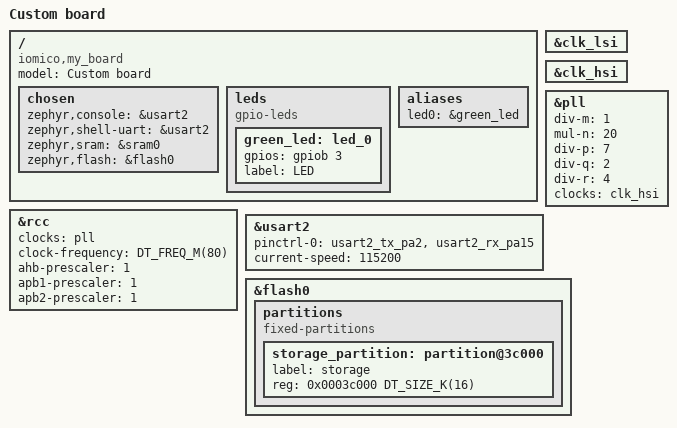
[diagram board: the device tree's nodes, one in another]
/dts-v1/;
#include <st/l4/stm32l432Xc.dtsi>
#include <st/l4/stm32l432k(b-c)ux-pinctrl.dtsi>

/ {
	model = "Custom board";
	compatible = "iomico,my_board";

	chosen {
		zephyr,console = &usart2;
		zephyr,shell-uart = &usart2;
		zephyr,sram = &sram0;
		zephyr,flash = &flash0;
	};

	leds: leds {
		compatible = "gpio-leds";

		green_led: led_0 {
			gpios = <&gpiob 3 GPIO_ACTIVE_HIGH>;
			label = "LED";
		};
	};

	aliases {
		led0 = &green_led;
	};
};

&clk_lsi {
	status = "okay";
};

&clk_hsi {
	status = "okay";
};

&pll {
	div-m = <1>;
	mul-n = <20>;
	div-p = <7>;
	div-q = <2>;
	div-r = <4>;
	clocks = <&clk_hsi>;
	status = "okay";
};

&rcc {
	clocks = <&pll>;
	clock-frequency = <DT_FREQ_M(80)>;
	ahb-prescaler = <1>;
	apb1-prescaler = <1>;
	apb2-prescaler = <1>;
};

&usart2 {
	pinctrl-0 = <&usart2_tx_pa2 &usart2_rx_pa15>;
	pinctrl-names = "default";
	current-speed = <115200>;
	status = "okay";
};

&flash0 {
	partitions {
		compatible = "fixed-partitions";
		#address-cells = <1>;
		#size-cells = <1>;

		/*
		 * Reserve the final 16 KiB for file system partition
		 */
		storage_partition: partition@3c000 {
			label = "storage";
			reg = <0x0003c000 DT_SIZE_K(16)>;
		};
	};
};
